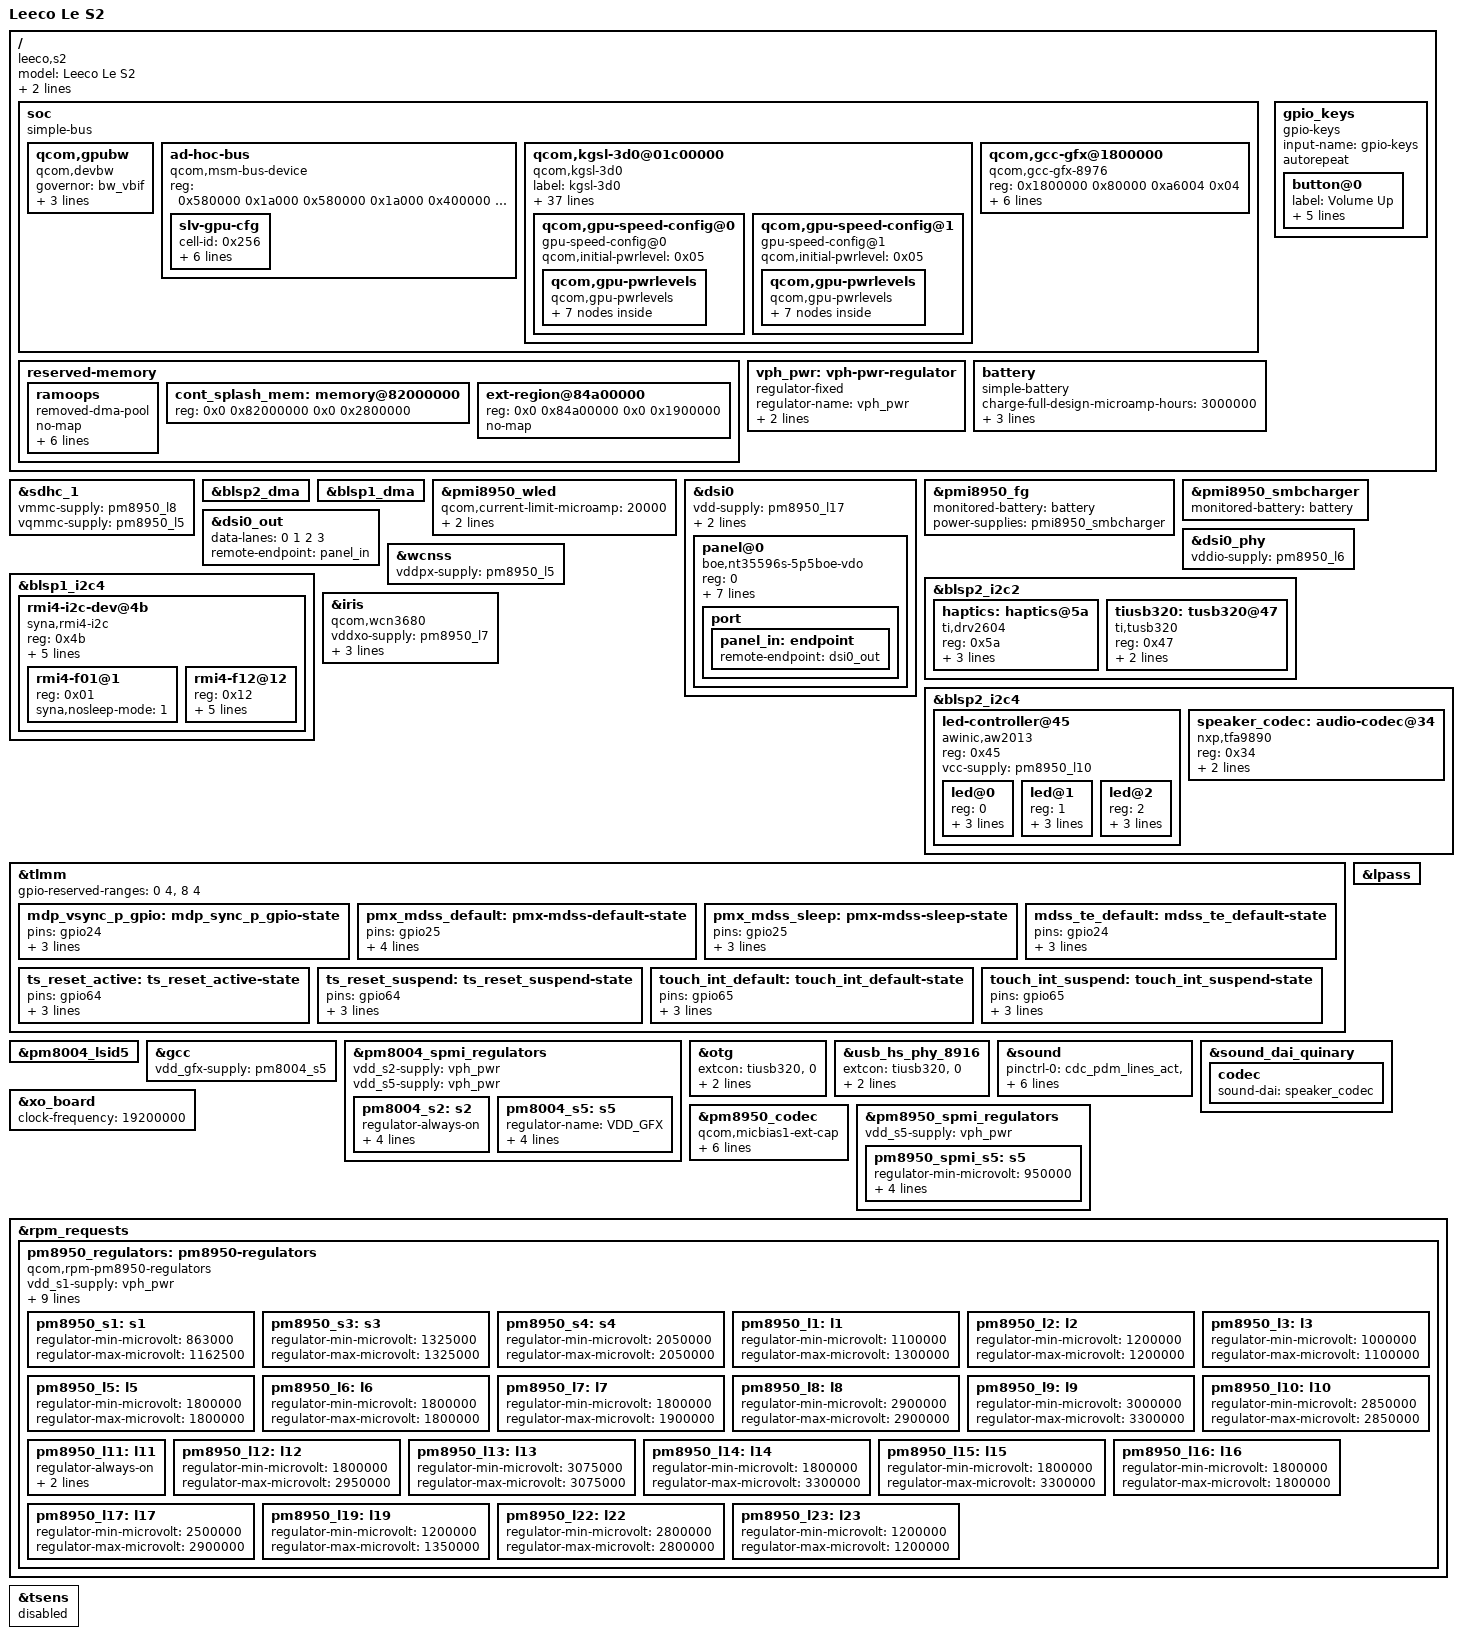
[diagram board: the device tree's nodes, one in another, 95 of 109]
// SPDX-License-Identifier: BSD-3-Clause
/dts-v1/;
#include "msm8976.dtsi"
#include "pm8950.dtsi"
#include "pm8004.dtsi"
#include "pmi8950.dtsi"
#include <dt-bindings/interrupt-controller/irq.h>
#include <dt-bindings/gpio/gpio.h>
#include <dt-bindings/input/gpio-keys.h>
#include <dt-bindings/input/input.h>
#include <dt-bindings/input/linux-event-codes.h>
#include <dt-bindings/pinctrl/qcom,pmic-gpio.h>
#include <dt-bindings/leds/common.h>
#include <dt-bindings/input/ti-drv260x.h>

/ {
	model = "Leeco Le S2";
	compatible = "leeco,s2", "qcom,msm8976";

	qcom,msm-id = <278 0x10001>;
	qcom,board-id = <11 0>;
	soc {
		#address-cells = <0x01>;
		#size-cells = <0x01>;
		ranges = <0x00 0x00 0x00 0xffffffff>;
		compatible = "simple-bus";
		qcom,gpubw {
			compatible = "qcom,devbw";
			governor = "bw_vbif";
			qcom,src-dst-ports = <0x1a 0x200>;
			qcom,bw-tbl = <0x00 0x325 0x4dd 0x64b 0x84c 0xb71 0x1005 0x1406 0x1650 0x1808 0x1bc0>;
			linux,phandle = <0xbe>;
			phandle = <0xbe>;
		};
		ad-hoc-bus {
			compatible = "qcom,msm-bus-device";
			reg = <0x580000 0x1a000 0x580000 0x1a000 0x400000 0x62000 0x500000 0x14000>;
			reg-names = "snoc-base\0snoc-mm-base\0bimc-base\0pcnoc-base";

			slv-gpu-cfg {
				cell-id = <0x256>;
				label = "slv-gpu-cfg";
				qcom,buswidth = <0x04>;
				qcom,agg-ports = <0x01>;
				qcom,ap-owned;
				qcom,bus-dev = <0x56>;
				qcom,slv-rpm-id = <0x0b>;
				linux,phandle = <0x68>;
				phandle = <0x68>;
			};
		};

		qcom,kgsl-3d0@01c00000 {
			label = "kgsl-3d0";
			compatible = "qcom,kgsl-3d0\0qcom,kgsl-3d";
			reg = <0x1c00000 0x40000 0x1c40000 0x10000 0xa0000 0x4800>;
			reg-names = "kgsl_3d0_reg_memory\0kgsl_3d0_shader_memory\0qfprom_memory";
			interrupts = <0x00 0x21 0x00>;
			interrupt-names = "kgsl_3d0_irq";
			qcom,id = <0x00>;
			qcom,chipid = <0x5010000>;
			qcom,initial-pwrlevel = <0x05>;
			qcom,idle-timeout = <0x50>;
			qcom,strtstp-sleepwake;
			qcom,pm-qos-active-latency = <0x191>;
			qcom,pm-qos-wakeup-latency = <0x65>;
			qcom,l2pc-cpu-mask = <0xf0>;
			qcom,clk-map = <0xf9e>;
			clocks = <0x2e 0x49a51fd9 0x2e 0xd15c8a00 0x2e 0x5620913a 0x2e 0x3edd69ad 0x2e 0xb432168e 0x2e 0x59505e55 0x2e 0x18bb9a90 0x2e 0xe66048ad 0x2e 0x1180db06 0x2e 0xae18e54d>;
			clock-names = "core_clk\0iface_clk\0mem_clk\0mem_iface_clk\0gtcu_iface_clk\0gtcu_clk\0gtbu_clk\0gtbu1_clk\0rbbmtimer_clk\0aon_clk";
			qcom,gpubw-dev = <0xbe>;
			qcom,bus-control;
			qcom,bus-width = <0x10>;
			qcom,msm-bus,name = "grp3d";
			qcom,msm-bus,num-cases = <0x0b>;
			qcom,msm-bus,num-paths = <0x01>;
			qcom,msm-bus,vectors-KBps = <0x1a 0x200 0x00 0x00 0x1a 0x200 0x00 0xce400 0x1a 0x200 0x00 0x13ec00 0x1a 0x200 0x00 0x19c800 0x1a 0x200 0x00 0x21fc00 0x1a 0x200 0x00 0x2ee000 0x1a 0x200 0x00 0x41a000 0x1a 0x200 0x00 0x520800 0x1a 0x200 0x00 0x5b6800 0x1a 0x200 0x00 0x627000 0x1a 0x200 0x00 0x71ac00>;
			vddcx-supply = <0xbf>;
			vdd-supply = <0xc0>;
			iommu = <0xc1>;
			coresight-id = <0x43>;
			coresight-name = "coresight-gfx";
			coresight-nr-inports = <0x00>;
			coresight-outports = <0x00>;
			coresight-child-list = <0xb5>;
			coresight-child-ports = <0x04>;
			qcom,gpu-fuse-numconfigs = <0x02>;
			qcom,gpu-fuse-config = <0x4160 0x14 0x01 0x120 0x1f 0x01>;
			qcom,gpu-speed-numplans = <0x03>;
			qcom,gpu-speed-plan = <0x00 0x00 0x02 0x01 0x03 0x00>;
			linux,phandle = <0xc8>;
			phandle = <0xc8>;

			qcom,gpu-speed-config@0 {
				compatible = "gpu-speed-config@0";
				qcom,initial-pwrlevel = <0x05>;

				qcom,gpu-pwrlevels {
					#address-cells = <0x01>;
					#size-cells = <0x00>;
					compatible = "qcom,gpu-pwrlevels";

					qcom,gpu-pwrlevel@0 {
						reg = <0x00>;
						qcom,gpu-freq = <0x23c34600>;
						qcom,bus-freq = <0x09>;
						qcom,bus-min = <0x09>;
						qcom,bus-max = <0x0a>;
					};

					qcom,gpu-pwrlevel@1 {
						reg = <0x01>;
						qcom,gpu-freq = <0x20c85580>;
						qcom,bus-freq = <0x09>;
						qcom,bus-min = <0x09>;
						qcom,bus-max = <0x0a>;
					};

					qcom,gpu-pwrlevel@2 {
						reg = <0x02>;
						qcom,gpu-freq = <0x1c9c3800>;
						qcom,bus-freq = <0x08>;
						qcom,bus-min = <0x07>;
						qcom,bus-max = <0x09>;
					};

					qcom,gpu-pwrlevel@3 {
						reg = <0x03>;
						qcom,gpu-freq = <0x19bfcc00>;
						qcom,bus-freq = <0x07>;
						qcom,bus-min = <0x05>;
						qcom,bus-max = <0x09>;
					};

					qcom,gpu-pwrlevel@4 {
						reg = <0x04>;
						qcom,gpu-freq = <0x11e1a300>;
						qcom,bus-freq = <0x05>;
						qcom,bus-min = <0x04>;
						qcom,bus-max = <0x07>;
					};

					qcom,gpu-pwrlevel@5 {
						reg = <0x05>;
						qcom,gpu-freq = <0xfe502ab>;
						qcom,bus-freq = <0x04>;
						qcom,bus-min = <0x04>;
						qcom,bus-max = <0x05>;
					};

					qcom,gpu-pwrlevel@6 {
						reg = <0x06>;
						qcom,gpu-freq = <0x124f800>;
						qcom,bus-freq = <0x00>;
						qcom,bus-min = <0x00>;
						qcom,bus-max = <0x00>;
					};
				};
			};

			qcom,gpu-speed-config@1 {
				compatible = "gpu-speed-config@1";
				qcom,initial-pwrlevel = <0x05>;

				qcom,gpu-pwrlevels {
					#address-cells = <0x01>;
					#size-cells = <0x00>;
					compatible = "qcom,gpu-pwrlevels";

					qcom,gpu-pwrlevel@0 {
						reg = <0x00>;
						qcom,gpu-freq = <0x2508be50>;
						qcom,bus-freq = <0x0a>;
						qcom,bus-min = <0x0a>;
						qcom,bus-max = <0x0a>;
					};

					qcom,gpu-pwrlevel@1 {
						reg = <0x01>;
						qcom,gpu-freq = <0x20c85580>;
						qcom,bus-freq = <0x09>;
						qcom,bus-min = <0x09>;
						qcom,bus-max = <0x0a>;
					};

					qcom,gpu-pwrlevel@2 {
						reg = <0x02>;
						qcom,gpu-freq = <0x1c9c3800>;
						qcom,bus-freq = <0x08>;
						qcom,bus-min = <0x07>;
						qcom,bus-max = <0x09>;
					};

					qcom,gpu-pwrlevel@3 {
						reg = <0x03>;
						qcom,gpu-freq = <0x19bfcc00>;
						qcom,bus-freq = <0x07>;
						qcom,bus-min = <0x05>;
						qcom,bus-max = <0x09>;
					};

					qcom,gpu-pwrlevel@4 {
						reg = <0x04>;
						qcom,gpu-freq = <0x11e1a300>;
						qcom,bus-freq = <0x05>;
						qcom,bus-min = <0x04>;
						qcom,bus-max = <0x07>;
					};

					qcom,gpu-pwrlevel@5 {
						reg = <0x05>;
						qcom,gpu-freq = <0xfe502ab>;
						qcom,bus-freq = <0x04>;
						qcom,bus-min = <0x04>;
						qcom,bus-max = <0x05>;
					};

					qcom,gpu-pwrlevel@6 {
						reg = <0x06>;
						qcom,gpu-freq = <0x124f800>;
						qcom,bus-freq = <0x00>;
						qcom,bus-min = <0x00>;
						qcom,bus-max = <0x00>;
					};
				};
			};
		};
		qcom,gcc-gfx@1800000 {
			compatible = "qcom,gcc-gfx-8976";
			reg = <0x1800000 0x80000 0xa6004 0x04>;
			reg-names = "cc_base\0fuse";
			vdd_gfx-supply = <0xc7>;
			gpu_handle = <0xc8>;
			qcom,gfxfreq-corner-v0 = <0x00 0x00 0x7f28155 0x01 0xbebc200 0x02 0xfe502ab 0x03 0x11e1a300 0x04 0x15daf0b0 0x05 0x19bfcc00 0x06 0x1c9c3800 0x07 0x20c85580 0x08 0x23c34600 0x09>;
			qcom,gfxfreq-corner-v1 = <0x00 0x00 0x7f28155 0x01 0xbebc200 0x02 0xfe502ab 0x03 0x11e1a300 0x04 0x15daf0b0 0x05 0x19bfcc00 0x06 0x1c9c3800 0x07 0x20c85580 0x08 0x23c34600 0x09 0x2508be50 0x09>;
			#clock-cells = <0x01>;
			linux,phandle = <0x2e>;
			phandle = <0x2e>;
		};
	};
	reserved-memory {
		ramoops {
			compatible = "removed-dma-pool", "ramoops";
			no-map;
			reg = <0 0x9ff00000 0 0x100000>;
			record-size = <0x10000>;
			console-size = <0x60000>;
			ftrace-size = <0x10000>;
			pmsg-size = <0x20000>;
			ecc-size = <16>;
			status = "okay";
		};

		/delete-node/ memory@83000000;
		
		cont_splash_mem: memory@82000000 {
			reg = <0x0 0x82000000 0x0 0x2800000>;
		};
		
		/delete-node/ ext-region@85b00000;
		 ext-region@84a00000 {
			reg = <0x0 0x84a00000 0x0 0x1900000>;
			no-map;
		};

	};

	vph_pwr: vph-pwr-regulator {
		compatible = "regulator-fixed";
		regulator-name = "vph_pwr";
		regulator-always-on;
		regulator-boot-on;
	};

	battery: battery {
		compatible = "simple-battery";
		charge-full-design-microamp-hours = <3000000>;
		constant-charge-current-max-microamp = <1000000>;
		voltage-min-design-microvolt = <3400000>;
		voltage-max-design-microvolt = <4400000>;
	};
	
	gpio_keys {
		compatible = "gpio-keys";
		input-name = "gpio-keys";
		#address-cells = <1>;
		#size-cells = <0>;
		autorepeat;

		button@0 {
			label = "Volume Up";
			gpios = <&tlmm 113 GPIO_ACTIVE_LOW>;
			linux,input-type = <EV_KEY>;
			linux,code = <KEY_VOLUMEUP>;
			wakeup-source;
			debounce-interval = <15>;
		};
	};
	/*
	ibb_vreg: fake-ibb-vreg {
		compatible = "regulator-fixed";
		regulator-name = "fakeibb_vreg";
		regulator-min-microvolt = <4000000>;
		regulator-max-microvolt = <4000000>;
	};
	lab_vreg: fake-lab-vreg {
		compatible = "regulator-fixed";
		regulator-name = "fakelab_vreg";
		regulator-min-microvolt = <4000000>;
		regulator-max-microvolt = <4000000>;
	};
*/
};

&sdhc_1 {
	vmmc-supply = <&pm8950_l8>;
	vqmmc-supply = <&pm8950_l5>;
	
	status = "okay";
};

&blsp2_dma {
	status = "okay";
};

&blsp1_dma {
	status = "okay";
};

&pmi8950_wled {
	status = "okay";

	qcom,current-limit-microamp = <20000>;
	qcom,enabled-strings = <0 1>;
	qcom,ovp-millivolt = <29600>;
};

&dsi0 {
	panel@0 {
		compatible = "boe,nt35596s-5p5boe-vdo";
		reg = <0>;
		backlight = <&pmi8950_wled>;

		supply-names = "vsp", "vsn";
		vsp-supply = <&lab_vreg>;
		vsn-supply = <&ibb_vreg>;

		reset-gpios = <&tlmm 25 GPIO_ACTIVE_LOW>;

		pinctrl-names = "default", "sleep";
		pinctrl-0 = <&pmx_mdss_default &mdss_te_default>;
		pinctrl-1 = <&pmx_mdss_sleep &mdss_te_default>;

		port {
			panel_in: endpoint {
				remote-endpoint = <&dsi0_out>;
			};
		};
	};
};

&pmi8950_fg {
	monitored-battery = <&battery>;
	power-supplies = <&pmi8950_smbcharger>;
	status = "okay";
};

&pmi8950_smbcharger {
	monitored-battery = <&battery>;
	status = "okay";
};

&dsi0_out {
	data-lanes = <0 1 2 3>;
	remote-endpoint = <&panel_in>;
};


&dsi0_phy {
	status = "okay";
	vddio-supply = <&pm8950_l6>;
};

&dsi0 {

	vdd-supply = <&pm8950_l17>;
	vdda-supply = <&pm8950_l1>;
	vddio-supply = <&pm8950_l6>;
};

&blsp1_i2c4 {
	status = "okay";

	rmi4-i2c-dev@4b {
		reg = <0x4b>;
		compatible = "syna,rmi4-i2c";
		interrupts-extended = <&tlmm 65 0x2008>;
		#address-cells = <1>;
		#size-cells = <0>;

		vdd-supply = <&pm8950_l17>;
		vio-supply = <&pm8950_l6>;
	
		syna,reset-delay-ms = <100>;
		syna,startup-delay-ms = <500>;
		rmi4-f01@1 {
			reg = <0x01>;
			syna,nosleep-mode = <1>;
		};

		rmi4-f12@12 {
			reg = <0x12>;
			syna,sensor-type = <1>;
			syna,clip-x-low = <0>;
			syna,clip-x-high = <1080>;
			syna,clip-y-low = <0>;
			syna,clip-y-high = <1920>;
		};
	};
};

&blsp2_i2c2 {

	status = "okay";
	
	haptics: haptics@5a {
		compatible = "ti,drv2604";
		reg = <0x5a>;
		enable-gpio = <&tlmm 109 GPIO_ACTIVE_HIGH>;
		mode = <DRV260X_LRA_MODE>;
		library-sel = <DRV260X_LIB_LRA>;
	};

	tiusb320: tusb320@47 {
		compatible = "ti,tusb320";
		reg = <0x47>;
		interrupt-parent = <&tlmm>;
		interrupts = <21 IRQ_TYPE_EDGE_RISING>;
        };
};

&blsp2_i2c4 {
	status = "okay";
	led-controller@45 {
		#address-cells = <1>;
		#size-cells = <0>;

		compatible = "awinic,aw2013";
		reg = <0x45>;
		vcc-supply = <&pm8950_l10>;

		led@0 {
			reg = <0>;
			led-max-microamp = <5000>;
			function = LED_FUNCTION_INDICATOR;
			color = <LED_COLOR_ID_RED>;
		};
		led@1 {
			reg = <1>;
			led-max-microamp = <5000>;
			function = LED_FUNCTION_INDICATOR;
			color = <LED_COLOR_ID_GREEN>;
		};
		led@2 {
			reg = <2>;
			led-max-microamp = <5000>;
			function = LED_FUNCTION_INDICATOR;
			color = <LED_COLOR_ID_BLUE>;
		};
	};
	
	speaker_codec: audio-codec@34 {
		compatible = "nxp,tfa9890";
		reg = <0x34>;
		vddd-supply = <&pm8950_l5>;
		sound-name-prefix = "Speaker";
		#sound-dai-cells = <0>;
	};
};


&wcnss {
	status = "okay";
	vddpx-supply = <&pm8950_l5>;
};

&iris {
	vddxo-supply = <&pm8950_l7>;
	vddrfa-supply = <&pm8950_l19>;
	vddpa-supply = <&pm8950_l9>;
	vdddig-supply = <&pm8950_l5>;
};

&tlmm {
	gpio-reserved-ranges = <0 4>, <8 4>;

	mdp_vsync_p_gpio: mdp_sync_p_gpio-state {
		pins = "gpio24";
		function = "mdp_vsync";
		drive-strength = <2>;
		bias-disable;
	};


	pmx_mdss_default: pmx-mdss-default-state {
		pins = "gpio25";
		function = "gpio";
		drive-strength = <8>;
		bias-disable;
		output-high;
	};

	pmx_mdss_sleep: pmx-mdss-sleep-state {
		pins = "gpio25";
		function = "gpio";
		drive-strength = <2>;
		bias-pull-down;
	};

	mdss_te_default: mdss_te_default-state {
			pins = "gpio24";
			function = "mdp_vsync";
			drive-strength = <2>;
			bias-pull-down;
		};
		
	ts_reset_active: ts_reset_active-state {
		pins = "gpio64";
		function = "gpio";
		drive-strength = <8>;
		bias-pull-up;
	};

	ts_reset_suspend: ts_reset_suspend-state {
		pins = "gpio64";
		function = "gpio";
		drive-strength = <2>;
		bias-pull-down;
	};

	touch_int_default: touch_int_default-state {
		pins = "gpio65";
		function = "gpio";
		drive-strength = <8>;
		bias-pull-up;
	};

	touch_int_suspend: touch_int_suspend-state {
		pins = "gpio65";
		function = "gpio";
		drive-strength = <2>;
		bias-pull-down;
	};
};

&pm8004_lsid5 {
	status = "okay";
};

&gcc {
	vdd_gfx-supply = <&pm8004_s5>;
};

&pm8004_spmi_regulators {
	vdd_s2-supply = <&vph_pwr>;
	vdd_s5-supply = <&vph_pwr>;
	status = "okay";
	
	pm8004_s2: s2 {
		regulator-always-on;
		regulator-boot-on;
		regulator-name = "vdd_apc1";
		regulator-min-microvolt = <950000>;
		regulator-max-microvolt = <1165000>;
	};

	pm8004_s5: s5 {
		regulator-name = "VDD_GFX";
		regulator-min-microvolt = <950000>;
		regulator-max-microvolt = <1165000>;
		regulator-enable-ramp-delay = <500>;
		regulator-always-on;

	};
};

&otg {
	status = "okay";
	extcon = <&tiusb320>,<0>;
	v1p8-supply = <&pm8950_l7>;
	v3p3-supply = <&pm8950_l13>;
};

&usb_hs_phy_8916 {

	status = "okay";
	extcon = <&tiusb320>,<0>;
	v1p8-supply = <&pm8950_l7>;
	v3p3-supply = <&pm8950_l13>;
};

&lpass {
	status= "okay";
};

&iris
{
	compatible = "qcom,wcn3680";
	vddxo-supply = <&pm8950_l7>;
	vddrfa-supply = <&pm8950_l19>;
	vddpa-supply = <&pm8950_l9>;
	vdddig-supply = <&pm8950_l5>;
};

&sound {
	status="okay";

	pinctrl-names = "default", "sleep";
	pinctrl-0 = <&cdc_pdm_lines_act &cdc_pdm_lines_2_act  &tlmm_pri_act &cross_con_sus >;
	pinctrl-1 = <&cdc_pdm_lines_sus &cdc_pdm_lines_2_sus  &tlmm_pri_sus &cross_con_act>;
	model = "leeco-s2";
};

&sound_dai_quinary {
status = "okay";
	codec {
		sound-dai = <&speaker_codec>;
	};
};

&xo_board {
	clock-frequency = <19200000>;
};

&pm8950_codec {
	status="okay";
	qcom,micbias1-ext-cap;
	qcom,hphl-jack-type-normally-open;
	qcom,mbhc-vthreshold-low = <75 150 237 450 500>;
	qcom,mbhc-vthreshold-high = <75 150 237 450 500>;
	vdd-cdc-io-supply = <&pm8950_l5>;
	vdd-cdc-tx-rx-cx-supply = <&pm8950_s4>;
	vdd-micbias-supply = <&pm8950_l13>;
};

&pm8950_spmi_regulators {
	vdd_s5-supply = <&vph_pwr>;

	/* Cluster 0 supply */
	pm8950_spmi_s5: s5 {
	
		regulator-min-microvolt = <950000>;
		regulator-max-microvolt = <1165000>;
		regulator-name = "vdd_apc0";
		regulator-always-on;
		regulator-boot-on;
	};
};

&rpm_requests {

	pm8950_regulators: pm8950-regulators {
		compatible = "qcom,rpm-pm8950-regulators";
		
		vdd_s1-supply = <&vph_pwr>;
		vdd_s2-supply = <&vph_pwr>;
		vdd_s3-supply = <&vph_pwr>;
		vdd_s4-supply = <&vph_pwr>;
		vdd_s6-supply = <&vph_pwr>;
		vdd_l1_l19-supply = <&pm8950_s3>;
		vdd_l2_l23-supply = <&pm8950_s3>;
		vdd_l3-supply = <&pm8950_s3>;
		vdd_l5_l6_l7_l16-supply = <&pm8950_s4>;
		vdd_l8_l11_l12_l17_l22-supply = <&vph_pwr>;
		
		pm8950_s1: s1 {
			regulator-min-microvolt = <863000>;
			regulator-max-microvolt = <1162500>;	
		};
	
		pm8950_s3: s3 {
			regulator-min-microvolt = <1325000>;
			regulator-max-microvolt = <1325000>;
		};
	
		pm8950_s4: s4 {
			regulator-min-microvolt = <2050000>;
			regulator-max-microvolt = <2050000>;
		};
	
		pm8950_l1: l1 {
			regulator-min-microvolt = <1100000>;
			regulator-max-microvolt = <1300000>;
		};
	
		pm8950_l2: l2 {
			regulator-min-microvolt = <1200000>;
			regulator-max-microvolt = <1200000>;
		};
	
		pm8950_l3: l3 {
			regulator-min-microvolt = <1000000>;
			regulator-max-microvolt = <1100000>;
		};
	
		pm8950_l5: l5 { 
			regulator-min-microvolt = <1800000>;
			regulator-max-microvolt = <1800000>;
		};
	
		pm8950_l6: l6 {
			regulator-min-microvolt = <1800000>;
			regulator-max-microvolt = <1800000>;
		};
		
		pm8950_l7: l7 {
			regulator-min-microvolt = <1800000>;
			regulator-max-microvolt = <1900000>;
		};
		
		pm8950_l8: l8 {
			regulator-min-microvolt = <2900000>;
			regulator-max-microvolt = <2900000>;
		};
	
		pm8950_l9: l9 { 
			regulator-min-microvolt = <3000000>;
			regulator-max-microvolt = <3300000>;
		};
	
		pm8950_l10: l10 {
			regulator-min-microvolt = <2850000>;
			regulator-max-microvolt = <2850000>;
		};
	
		pm8950_l11: l11 {
			regulator-always-on;
			regulator-min-microvolt = <2950000>;
			regulator-max-microvolt = <2950000>;
		};
	
		pm8950_l12: l12 {
			regulator-min-microvolt = <1800000>;
			regulator-max-microvolt = <2950000>;
		};
	
		pm8950_l13: l13 {
			regulator-min-microvolt = <3075000>;
			regulator-max-microvolt = <3075000>;
		};
	
		pm8950_l14: l14 {
			regulator-min-microvolt = <1800000>;
			regulator-max-microvolt = <3300000>;
		};
	
		pm8950_l15: l15 {
			regulator-min-microvolt = <1800000>;
			regulator-max-microvolt = <3300000>;
		};
	
		pm8950_l16: l16 {
			regulator-min-microvolt = <1800000>;
			regulator-max-microvolt = <1800000>;
		};
	
		pm8950_l17: l17 {
			regulator-min-microvolt = <2500000>;
			regulator-max-microvolt = <2900000>;
		};
	
		pm8950_l19: l19 {
			regulator-min-microvolt = <1200000>;
			regulator-max-microvolt = <1350000>;
		};
	
		pm8950_l22: l22 {
			regulator-min-microvolt = <2800000>;
			regulator-max-microvolt = <2800000>;
		};
	
		pm8950_l23: l23 {
			regulator-min-microvolt = <1200000>;
			regulator-max-microvolt = <1200000>;
		};
	};
};
&tsens {
status = "disabled";
};
